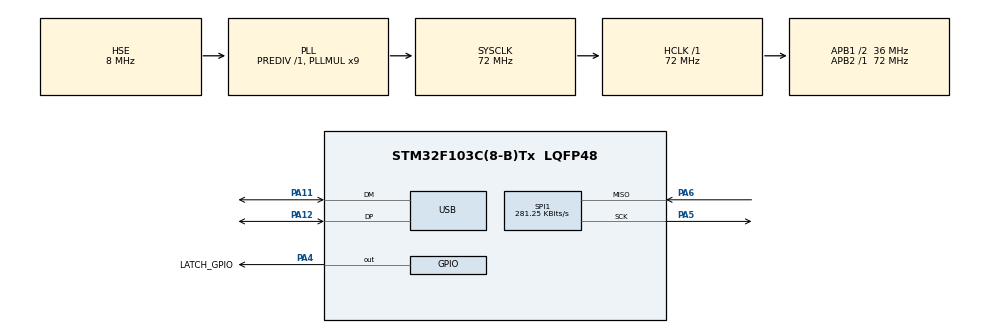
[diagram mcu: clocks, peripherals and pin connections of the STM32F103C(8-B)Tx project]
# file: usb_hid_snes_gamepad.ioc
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Mcu.Family=STM32F1
Mcu.Name=STM32F103C(8-B)Tx
Mcu.Package=LQFP48
NVIC.PriorityGroup=NVIC_PRIORITYGROUP_4
NVIC.USB_LP_CAN1_RX0_IRQn=true\:0\:0\:false\:false\:true\:false\:true
PA11.Mode=Device
PA11.Signal=USB_DM
PA12.Mode=Device
PA12.Signal=USB_DP
PA13.Mode=Serial_Wire
PA13.Signal=SYS_JTMS-SWDIO
PA14.Mode=Serial_Wire
PA14.Signal=SYS_JTCK-SWCLK
PA4.GPIO_Label=LATCH_GPIO
PA4.GPIO_Speed=GPIO_SPEED_FREQ_HIGH
PA4.Signal=GPIO_Output
PA5.Mode=RX_Only_Simplex_Unidirect_Master
PA5.Signal=SPI1_SCK
PA6.Mode=RX_Only_Simplex_Unidirect_Master
PA6.Signal=SPI1_MISO
PD0-OSC_IN.Mode=HSE-External-Oscillator
PD0-OSC_IN.Signal=RCC_OSC_IN
PD1-OSC_OUT.Mode=HSE-External-Oscillator
PD1-OSC_OUT.Signal=RCC_OSC_OUT
ProjectManager.HeapSize=0x200
ProjectManager.StackSize=0x400
ProjectManager.TargetToolchain=STM32CubeIDE
RCC.AHBFreq_Value=72000000
RCC.APB1CLKDivider=RCC_HCLK_DIV2
RCC.APB1Freq_Value=36000000
RCC.APB1TimFreq_Value=72000000
RCC.APB2Freq_Value=72000000
RCC.APB2TimFreq_Value=72000000
RCC.HCLKFreq_Value=72000000
RCC.PLLMUL=RCC_PLL_MUL9
RCC.PLLSourceVirtual=RCC_PLLSOURCE_HSE
RCC.SYSCLKFreq_VALUE=72000000
RCC.SYSCLKSource=RCC_SYSCLKSOURCE_PLLCLK
RCC.USBFreq_Value=48000000
RCC.USBPrescaler=RCC_USBCLKSOURCE_PLL_DIV1_5
SPI1.BaudRatePrescaler=SPI_BAUDRATEPRESCALER_256
SPI1.CLKPolarity=SPI_POLARITY_HIGH
SPI1.CalculateBaudRate=281.25 KBits/s
SPI1.DataSize=SPI_DATASIZE_16BIT
SPI1.Direction=SPI_DIRECTION_2LINES_RXONLY
SPI1.FirstBit=SPI_FIRSTBIT_LSB
SPI1.Mode=SPI_MODE_MASTER
SPI1.VirtualType=VM_MASTER
USB_DEVICE.CLASS_NAME_FS=HID
USB_DEVICE.VirtualMode=Hid
USB_DEVICE.VirtualModeFS=Hid_FS
VP_USB_DEVICE_VS_USB_DEVICE_HID_FS.Mode=HID_FS
board=custom

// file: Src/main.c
/* USER CODE BEGIN Header */
/**
  ******************************************************************************
  * @file           : main.c
  * @brief          : Main program body
  ******************************************************************************
  * @attention
  *
  * <h2><center>&copy; Copyright (c) 2020 STMicroelectronics.
  * All rights reserved.</center></h2>
  *
  * This software component is licensed by ST under BSD 3-Clause license,
  * the "License"; You may not use this file except in compliance with the
  * License. You may obtain a copy of the License at:
  *                        opensource.org/licenses/BSD-3-Clause
  *
  ******************************************************************************
  */
/* USER CODE END Header */

#include "main.h"
#include "usb_device.h"

/* USER CODE BEGIN Includes */
#include "usbd_hid.h"
#include "dwt_delay.h"
/* USER CODE END Includes */

SPI_HandleTypeDef hspi1;

void SystemClock_Config(void);
static void MX_GPIO_Init(void);
static void MX_SPI1_Init(void);

int main(void)
{
  /* USER CODE BEGIN 1 */
	uint8_t gamepad_buttons[2] = {0x00, 0x00};
  /* USER CODE END 1 */

  /* MCU Configuration--------------------------------------------------------*/

  /* Reset of all peripherals, Initializes the Flash interface and the Systick. */
  HAL_Init();

  /* USER CODE BEGIN Init */
  // initialize delay functionality
  DWT_Init();
  /* USER CODE END Init */

  /* Configure the system clock */
  SystemClock_Config();

  /* Initialize all configured peripherals */
  MX_GPIO_Init();
  MX_SPI1_Init();
  MX_USB_DEVICE_Init();

  /* Infinite loop */
  while (1)
  {

    /* USER CODE BEGIN 3 */
	  // toggle LATCH-pin on SNES-gamepad
	  HAL_GPIO_WritePin(LATCH_GPIO_GPIO_Port, LATCH_GPIO_Pin, GPIO_PIN_SET);
	  DWT_Delay(12); // 12µs delay
	  HAL_GPIO_WritePin(LATCH_GPIO_GPIO_Port, LATCH_GPIO_Pin, GPIO_PIN_RESET);
	  DWT_Delay(6); // 6µs delay
	  HAL_SPI_Receive(&hspi1, gamepad_buttons, 2, 50); // read 16bits (2 bytes) from gamepad
	  gamepad_buttons[0] = ~gamepad_buttons[0]; // invert all bits
	  gamepad_buttons[1] = ~gamepad_buttons[1]; // invert all bits
	  // send keypress states via USB, busy waiting until successfull
	  while( USBD_HID_SendReport(get_usbd_handle_ptr(), gamepad_buttons, sizeof(gamepad_buttons)) != USBD_OK);
	  HAL_Delay(1);
  }
  /* USER CODE END 3 */
}

void SystemClock_Config(void)
{
  RCC_OscInitTypeDef RCC_OscInitStruct = {0};
  RCC_ClkInitTypeDef RCC_ClkInitStruct = {0};
  RCC_PeriphCLKInitTypeDef PeriphClkInit = {0};

  /** Initializes the CPU, AHB and APB busses clocks
  */
  RCC_OscInitStruct.OscillatorType = RCC_OSCILLATORTYPE_HSE;
  RCC_OscInitStruct.HSEState = RCC_HSE_ON;
  RCC_OscInitStruct.HSEPredivValue = RCC_HSE_PREDIV_DIV1;
  RCC_OscInitStruct.HSIState = RCC_HSI_ON;
  RCC_OscInitStruct.PLL.PLLState = RCC_PLL_ON;
  RCC_OscInitStruct.PLL.PLLSource = RCC_PLLSOURCE_HSE;
  RCC_OscInitStruct.PLL.PLLMUL = RCC_PLL_MUL9;
  if (HAL_RCC_OscConfig(&RCC_OscInitStruct) != HAL_OK)
  {
    Error_Handler();
  }
  /** Initializes the CPU, AHB and APB busses clocks
  */
  RCC_ClkInitStruct.ClockType = RCC_CLOCKTYPE_HCLK|RCC_CLOCKTYPE_SYSCLK
                              |RCC_CLOCKTYPE_PCLK1|RCC_CLOCKTYPE_PCLK2;
  RCC_ClkInitStruct.SYSCLKSource = RCC_SYSCLKSOURCE_PLLCLK;
  RCC_ClkInitStruct.AHBCLKDivider = RCC_SYSCLK_DIV1;
  RCC_ClkInitStruct.APB1CLKDivider = RCC_HCLK_DIV2;
  RCC_ClkInitStruct.APB2CLKDivider = RCC_HCLK_DIV1;

  if (HAL_RCC_ClockConfig(&RCC_ClkInitStruct, FLASH_LATENCY_2) != HAL_OK)
  {
    Error_Handler();
  }
  PeriphClkInit.PeriphClockSelection = RCC_PERIPHCLK_USB;
  PeriphClkInit.UsbClockSelection = RCC_USBCLKSOURCE_PLL_DIV1_5;
  if (HAL_RCCEx_PeriphCLKConfig(&PeriphClkInit) != HAL_OK)
  {
    Error_Handler();
  }
}

static void MX_SPI1_Init(void)
{

  /* SPI1 parameter configuration*/
  hspi1.Instance = SPI1;
  hspi1.Init.Mode = SPI_MODE_MASTER;
  hspi1.Init.Direction = SPI_DIRECTION_2LINES_RXONLY;
  hspi1.Init.DataSize = SPI_DATASIZE_16BIT;
  hspi1.Init.CLKPolarity = SPI_POLARITY_HIGH;
  hspi1.Init.CLKPhase = SPI_PHASE_1EDGE;
  hspi1.Init.NSS = SPI_NSS_SOFT;
  hspi1.Init.BaudRatePrescaler = SPI_BAUDRATEPRESCALER_256;
  hspi1.Init.FirstBit = SPI_FIRSTBIT_LSB;
  hspi1.Init.TIMode = SPI_TIMODE_DISABLE;
  hspi1.Init.CRCCalculation = SPI_CRCCALCULATION_DISABLE;
  hspi1.Init.CRCPolynomial = 10;
  if (HAL_SPI_Init(&hspi1) != HAL_OK)
  {
    Error_Handler();
  }

}

static void MX_GPIO_Init(void)
{
  GPIO_InitTypeDef GPIO_InitStruct = {0};

  /* GPIO Ports Clock Enable */
  __HAL_RCC_GPIOD_CLK_ENABLE();
  __HAL_RCC_GPIOA_CLK_ENABLE();

  /*Configure GPIO pin Output Level */
  HAL_GPIO_WritePin(LATCH_GPIO_GPIO_Port, LATCH_GPIO_Pin, GPIO_PIN_RESET);

  /*Configure GPIO pin : LATCH_GPIO_Pin */
  GPIO_InitStruct.Pin = LATCH_GPIO_Pin;
  GPIO_InitStruct.Mode = GPIO_MODE_OUTPUT_PP;
  GPIO_InitStruct.Pull = GPIO_NOPULL;
  GPIO_InitStruct.Speed = GPIO_SPEED_FREQ_HIGH;
  HAL_GPIO_Init(LATCH_GPIO_GPIO_Port, &GPIO_InitStruct);

}

void Error_Handler(void)
{
}

/************************ (C) COPYRIGHT STMicroelectronics *****END OF FILE****/
